VERSION "vecu-1.0"

NS_ :

BS_:

BU_: CTRL VECU TESTER

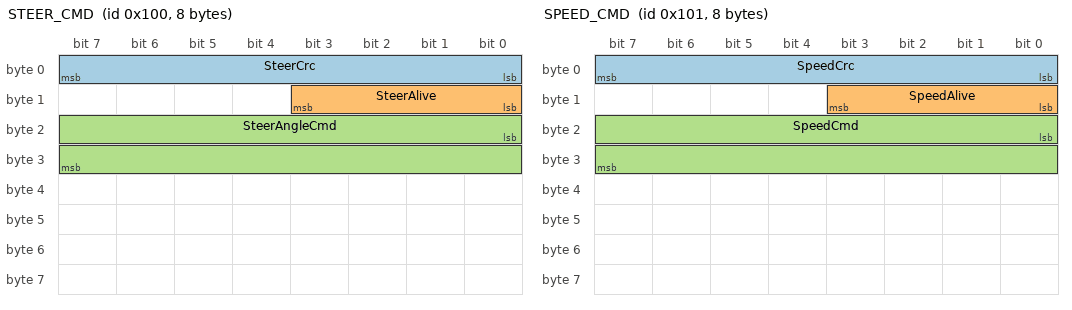
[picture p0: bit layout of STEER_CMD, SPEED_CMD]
BO_ 256 STEER_CMD: 8 CTRL
 SG_ SteerCrc : 0|8@1+ (1,0) [0|255] "" VECU
 SG_ SteerAlive : 8|4@1+ (1,0) [0|15] "" VECU
 SG_ SteerAngleCmd : 16|16@1- (0.1,0) [-3276.8|3276.7] "deg" VECU

BO_ 257 SPEED_CMD: 8 CTRL
 SG_ SpeedCrc : 0|8@1+ (1,0) [0|255] "" VECU
 SG_ SpeedAlive : 8|4@1+ (1,0) [0|15] "" VECU
 SG_ SpeedCmd : 16|16@1+ (0.01,0) [0|655.35] "km/h" VECU

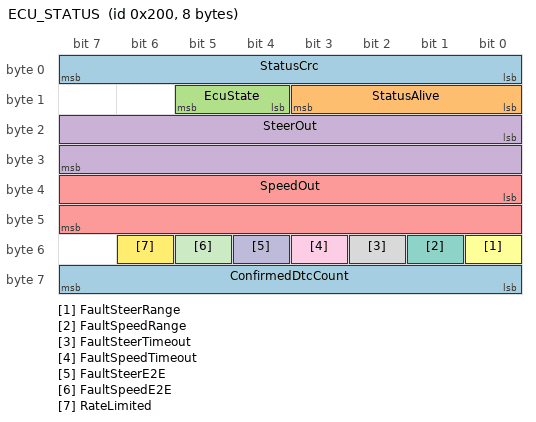
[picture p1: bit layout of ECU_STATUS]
BO_ 512 ECU_STATUS: 8 VECU
 SG_ StatusCrc : 0|8@1+ (1,0) [0|255] "" CTRL,TESTER
 SG_ StatusAlive : 8|4@1+ (1,0) [0|15] "" CTRL,TESTER
 SG_ EcuState : 12|2@1+ (1,0) [0|3] "" CTRL,TESTER
 SG_ SteerOut : 16|16@1- (0.1,0) [-3276.8|3276.7] "deg" CTRL,TESTER
 SG_ SpeedOut : 32|16@1+ (0.01,0) [0|655.35] "km/h" CTRL,TESTER
 SG_ FaultSteerRange : 48|1@1+ (1,0) [0|1] "" CTRL,TESTER
 SG_ FaultSpeedRange : 49|1@1+ (1,0) [0|1] "" CTRL,TESTER
 SG_ FaultSteerTimeout : 50|1@1+ (1,0) [0|1] "" CTRL,TESTER
 SG_ FaultSpeedTimeout : 51|1@1+ (1,0) [0|1] "" CTRL,TESTER
 SG_ FaultSteerE2E : 52|1@1+ (1,0) [0|1] "" CTRL,TESTER
 SG_ FaultSpeedE2E : 53|1@1+ (1,0) [0|1] "" CTRL,TESTER
 SG_ RateLimited : 54|1@1+ (1,0) [0|1] "" CTRL,TESTER
 SG_ ConfirmedDtcCount : 56|8@1+ (1,0) [0|255] "" CTRL,TESTER

BO_ 2016 UDS_REQ_PHYS: 8 TESTER
 SG_ IsoTpData : 0|64@1+ (1,0) [0|0] "" VECU

BO_ 2015 UDS_REQ_FUNC: 8 TESTER
 SG_ IsoTpData : 0|64@1+ (1,0) [0|0] "" VECU

BO_ 2024 UDS_RESP: 8 VECU
 SG_ IsoTpData : 0|64@1+ (1,0) [0|0] "" TESTER

CM_ BU_ CTRL "Controller sending commands (simulated by the rest-bus in tools/vecu/restbus.py).";
CM_ BU_ VECU "Safety monitor virtual ECU (ecu/).";
CM_ BO_ 256 "Steering command, period 10 ms. E2E: Data ID 0x1A01.";
CM_ BO_ 257 "Speed command, period 10 ms. E2E: Data ID 0x1A02.";
CM_ BO_ 512 "ECU status, period 20 ms plus one frame on every state change. E2E: Data ID 0x1A03.";
CM_ SG_ 256 SteerCrc "CRC8 SAE J1850 (poly 0x1D, init 0xFF, xor-out 0xFF) over Data ID low byte, Data ID high byte, bytes 1..7.";
CM_ SG_ 256 SteerAlive "Alive counter, +1 per frame modulo 16.";
CM_ SG_ 256 SteerAngleCmd "Valid range -540.0..540.0 deg (REQ-01). Positive = left.";
CM_ SG_ 257 SpeedCmd "Valid range 0.00..200.00 km/h (REQ-02).";
CM_ SG_ 512 SteerOut "Steering output after range check and rate limit (5.0 deg per 10 ms, REQ-03).";
CM_ SG_ 512 SpeedOut "Speed output; ramps down at 10 km/h/s in SAFE_STOP and after a speed timeout.";
CM_ SG_ 512 ConfirmedDtcCount "Number of DTCs with confirmedDTC set.";
CM_ BO_ 2016 "UDS physical request, ISO 15765-2 (ISO-TP) frames, padded to 8 bytes with 0xCC.";
CM_ BO_ 2015 "UDS functional request (single frame only).";
CM_ BO_ 2024 "UDS response, ISO-TP frames, padded to 8 bytes with 0xCC.";
BA_DEF_ BO_ "GenMsgCycleTime" INT 0 10000;
BA_DEF_DEF_ "GenMsgCycleTime" 0;
BA_ "GenMsgCycleTime" BO_ 256 10;
BA_ "GenMsgCycleTime" BO_ 257 10;
BA_ "GenMsgCycleTime" BO_ 512 20;
VAL_ 512 EcuState 0 "NORMAL" 1 "DEGRADED" 2 "SAFE_STOP" 3 "INIT" ;
